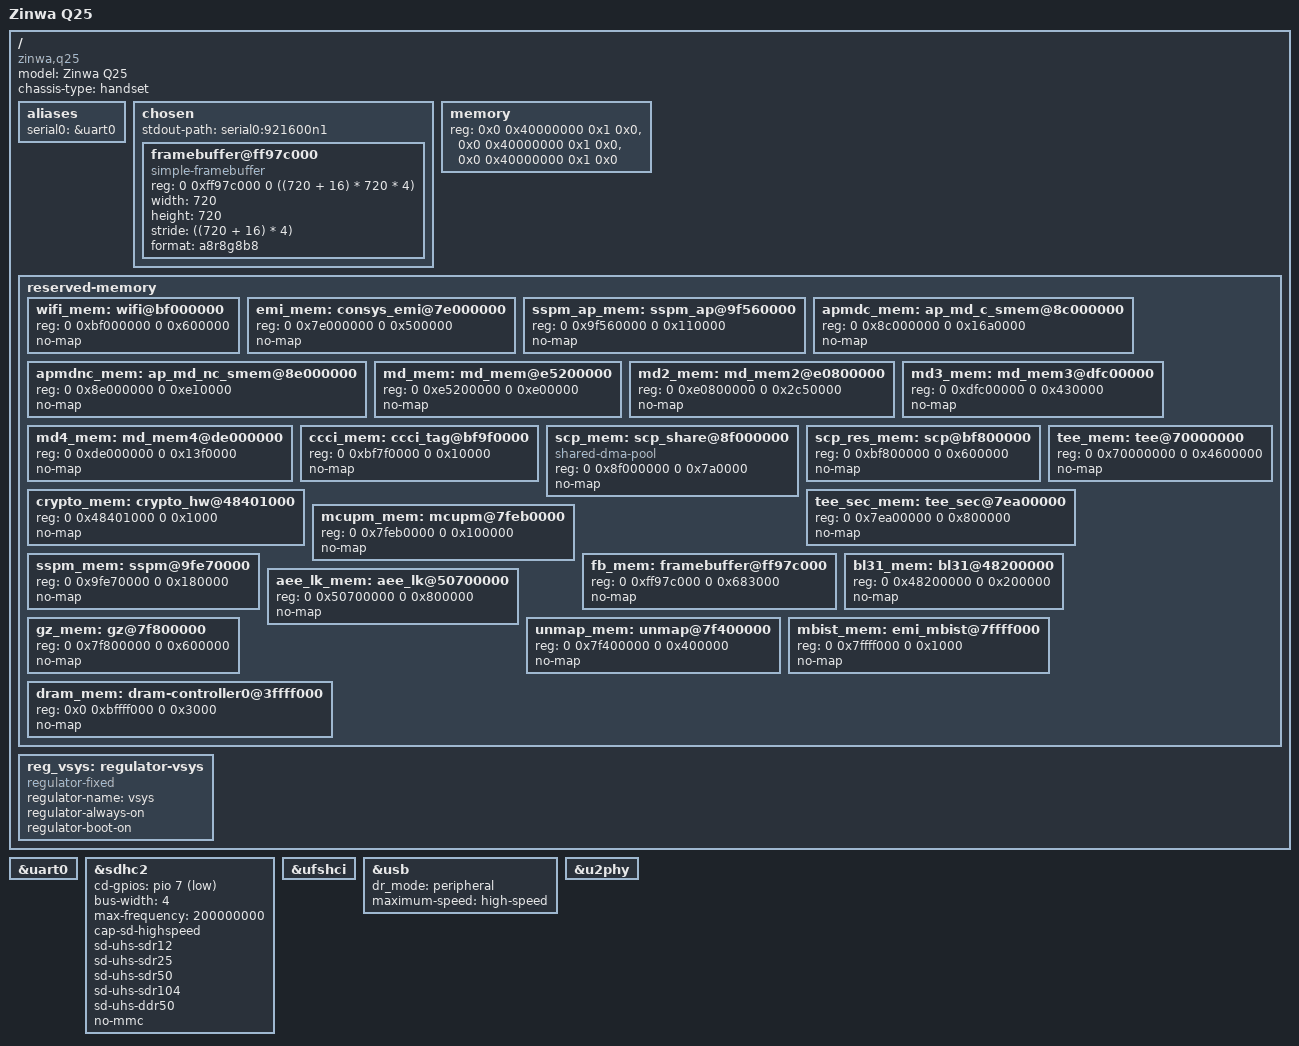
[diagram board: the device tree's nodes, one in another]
// SPDX-License-Identifier: GPL-2.0

/dts-v1/;

#include <dt-bindings/input/input.h>
#include <dt-bindings/gpio/gpio.h>
#include <dt-bindings/regulator/mediatek,mt6397-regulator.h>
#include "mt6789.dtsi"

/ {
	model = "Zinwa Q25";
	chassis-type = "handset";
	compatible = "zinwa,q25", "mediatek,mt8781", "mediatek,mt6789";

	#address-cells = <2>;
	#size-cells = <2>;

	aliases {
		serial0 = &uart0;
	};

	chosen {
		#address-cells = <2>;
		#size-cells = <2>;
		ranges;

		stdout-path = "serial0:921600n1";

		framebuffer@ff97c000 {
			compatible = "simple-framebuffer";
			reg = <0 0xff97c000 0 ((720 + 16) * 720 * 4)>;
			width = <720>;
			height = <720>;
			stride = <((720 + 16) * 4)>;
			format = "a8r8g8b8";
		};
	};

	memory {
		// Should be reg = <0x0 0x40000000 0x3 0x0>" (3x 4GB memory banks).
		// TODO: Fix once bank parsing logic is added to SoC init.
		device_type = "memory";
		reg = <0x0 0x40000000 0x1 0x0>,
			  <0x0 0x40000000 0x1 0x0>,
			  <0x0 0x40000000 0x1 0x0>;
	};

	reserved-memory {
		#address-cells = <2>;
		#size-cells = <2>;

		wifi_mem: wifi@bf000000 {
			reg = <0 0xbf000000 0 0x600000>;
			no-map;
		};

		emi_mem: consys_emi@7e000000 {
			reg = <0 0x7e000000 0 0x500000>;
			no-map;
		};

		sspm_ap_mem: sspm_ap@9f560000 {
			reg = <0 0x9f560000 0 0x110000>;
			no-map;
		};

		apmdc_mem: ap_md_c_smem@8c000000 {
			reg = <0 0x8c000000 0 0x16a0000>;
			no-map;
		};

		apmdnc_mem: ap_md_nc_smem@8e000000 {
			reg = <0 0x8e000000 0 0xe10000>;
			no-map;
		};

		md_mem: md_mem@e5200000 {
			reg = <0 0xe5200000 0 0xe00000>;
			no-map;
		};

		md2_mem: md_mem2@e0800000 {
			reg = <0 0xe0800000 0 0x2c50000>;
			no-map;
		};

		md3_mem: md_mem3@dfc00000 {
			reg = <0 0xdfc00000 0 0x430000>;
			no-map;
		};

		md4_mem: md_mem4@de000000 {
			reg = <0 0xde000000 0 0x13f0000>;
			no-map;
		};

		ccci_mem: ccci_tag@bf9f0000 {
			reg = <0 0xbf7f0000 0 0x10000>;
			no-map;
		};

		scp_mem: scp_share@8f000000 {
			reg = <0 0x8f000000 0 0x7a0000>;
			compatible = "shared-dma-pool";
			no-map;
		};

		scp_res_mem: scp@bf800000 {
			reg = <0 0xbf800000 0 0x600000>;
			no-map;
		};

//		dfdmcu_mem: dfdmcu_dump@fd000000 {
//			reg = <0 0xff000000 0 0x100000>;
//			no-map;
//		};

		crypto_mem: crypto_hw@48401000 {
			reg = <0 0x48401000 0 0x1000>;
			no-map;
		};

		tee_mem: tee@70000000 {
			reg = <0 0x70000000 0 0x4600000>;
			no-map;
		};

		tee_sec_mem: tee_sec@7ea00000 {
			reg = <0 0x7ea00000 0 0x800000>;
			no-map;
		};

		mcupm_mem: mcupm@7feb0000 {
			reg = <0 0x7feb0000 0 0x100000>;
			no-map;
		};

		sspm_mem: sspm@9fe70000 {
			reg = <0 0x9fe70000 0 0x180000>;
			no-map;
		};

		fb_mem: framebuffer@ff97c000 {
			reg = <0 0xff97c000 0 0x683000>;
			no-map;
		};

		bl31_mem: bl31@48200000 {
			reg = <0 0x48200000 0 0x200000>;
			no-map;
		};

		aee_lk_mem: aee_lk@50700000 {
			reg = <0 0x50700000 0 0x800000>;
			no-map;
		};

//		minirdump_mem: minirdump@48170000 {
//			reg = <0 0x48170000 0 0x10000>;
//			no-map;
//		};

//		pstore_mem: pstore@48090000 {
//			reg = <0 0x48090000 0 0xe0000>;
//			no-map;
//		};

//		aee_kinfo_mem: aee_kinfo@48080000 {
//			reg = <0 0x48080000 0 0x10000>;
//			no-map;
//		};

//		atf_log_mem: atf_log@bfe00000 {
//			reg = <0 0xbfe00000 0 0x200000>;
//			no-map;
//		};

//		log_mem: log_store@7ffbf000 {
//			reg = <0 0x7ffbf000 0 0x40000>;
//			no-map;
//		};

//		gz_log_mem: gz_log@7f200000 {
//			reg = <0 0x7f200000 0 0x41000>;
//			no-map;
//		};

		unmap_mem: unmap@7f400000 {
			reg = <0 0x7f400000 0 0x400000>;
			no-map;
		};

		gz_mem: gz@7f800000 {
			reg = <0 0x7f800000 0 0x600000>;
			no-map;
		};

		mbist_mem: emi_mbist@7ffff000 {
			reg = <0 0x7ffff000 0 0x1000>;
			no-map;
		};

		// This SoC likely uses two DRAM bsanks,
		// so each bank needs 4K of reserved memory per bank.
		// ( Speculation, quotation needed :P )
//		dram1_mem: dram-controller1@3ffff000 {
//			reg = <0x3 0x3ffff000 0 0x1000>;
//			no-map;
//		};

//		dram0_mem: dram-controller0@3ffff000 {
//			reg = <0x1 0xbffff000 0 0x1000>;
//			no-map;
//		};

		dram_mem: dram-controller0@3ffff000 {
			reg = <0x0 0xbffff000 0 0x3000>;
			no-map;
		};
	};

	reg_vsys: regulator-vsys {
		compatible = "regulator-fixed";
		regulator-name = "vsys";
		regulator-always-on;
		regulator-boot-on;
	};
};

&uart0 {
	status = "okay";
};

&sdhc2 {
	status = "okay";
	cd-gpios = <&pio 7 GPIO_ACTIVE_LOW>;
	bus-width = <4>;
	max-frequency = <200000000>;

// pinctrl-names = "default", "state_uhs", "pull_down";
// pinctrl-0 = <&mmc1_pins_default>;
// pinctrl-1 = <&mmc1_pins_uhs>;
// pinctrl-2 = <&mmc1_pins_pull_down>;
	cap-sd-highspeed;
	sd-uhs-sdr12;
	sd-uhs-sdr25;
	sd-uhs-sdr50;
	sd-uhs-sdr104;
	sd-uhs-ddr50;
	no-mmc;

// vmmc-supply = <&mt6358_vmch_eint_high>;
// vqmmc-supply = <&mt6358_vmc_reg>;
};

&ufshci {
	status = "okay";
};

&usb {
	status = "okay";

	dr_mode = "peripheral";
	maximum-speed = "high-speed";
};

&u2phy {
	status = "okay";
};
